# MINI51AN_v1 register map
File version: 1.0
Registers are 32-bit, read-write, reset 0x0 unless marked. A register's access mark holds for its fields unless they carry their own. Offsets are from the block's base; [hi:lo] are bit positions; {n}, {i} and the like mark numbered series; 'fields as' and 'values as' point back to an identical list.

## PWM — PWM Register Map
Base 0x40040000
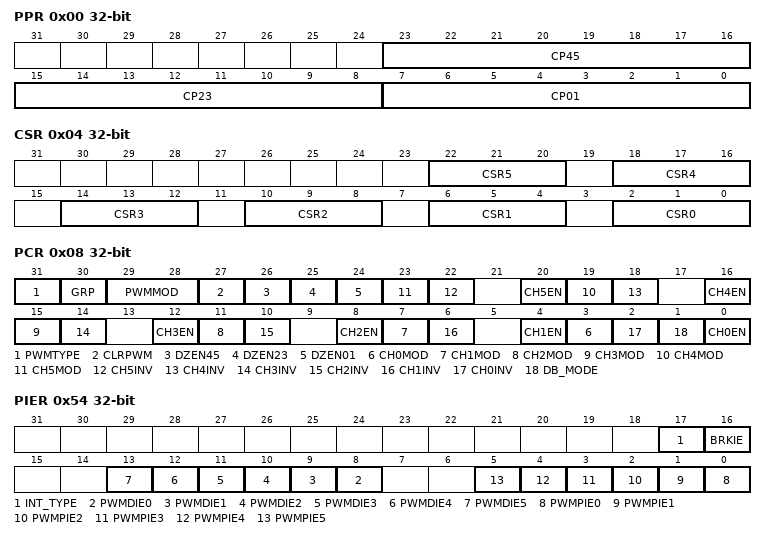
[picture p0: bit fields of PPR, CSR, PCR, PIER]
0x00 PPR — PWM Pre-scale Register
  [23:16] CP45 — Clock Prescaler 4 (PWM Counter 4 5 for group). Clock input is divided by (CP45 + 1) before it is fed to the corresponding PWM counter.
  [15:8] CP23 — Clock Prescaler 2 (PWM Counter 2 3 for group). Clock input is divided by (CP23 + 1) before it is fed to the corresponding PWM counter.
  [7:0] CP01 — Clock Prescaler 0 (PWM Counter 0 1 for group). Clock input is divided by (CP01 + 1) before it is fed to the corresponding PWM counter.
0x04 CSR — PWM Clock Select Register
  [22:20] CSR5 — Timer 5 Clock Source Selection
  [4n+2:4n] CSR{n} (n=0..4) — Timer {n} Clock Source Selection. Select clock input for PWM timer. (Table is the same as CSR5.)
0x08 PCR — PWM Control Register
  [31] PWMTYPE — PWM Aligned Type Selection Bit
    0=Edge-aligned type; 1=Center-aligned type
  [30] GRP — Group bit
    0=The signals timing of PWM0, PWM2 and PWM4 are independent; 1=Unify the signals timing of PWM0, PWM2 and PWM4 in the same phase which is controlled by PWM0
  [29:28] PWMMOD — PWM Operating Mode Selection
  [27] CLRPWM — Clear PWM Counter Control Bit. Note: It is automatically cleared by hardware.
    0=Do not clear PWM counter; 1=16-bit PWM counter cleared to 0x000
  [26] DZEN45 — Dead-zone 4 Generator Enable/Disable (PWM4 and PWM5 pair for PWM group). Note: When the dead-zone generator is enabled, the pair of PWM4 and PWM5 becomes a complementary pair for PWM group.
    0=Disabled; 1=Enabled
  [25] DZEN23 — Dead-zone 2 Generator Enable/Disable (PWM2 and PWM3 pair for PWM group). Note: When the dead-zone generator is enabled, the pair of PWM2 and PWM3 becomes a complementary pair for PWM group.
    0=Disabled; 1=Enabled
  [24] DZEN01 — Dead-zone 0 Generator Enable/Disable (PWM0 and PWM1 pair for PWM group). Note: When the dead-zone generator is enabled, the pair of PWM0 and PWM1 becomes a complementary pair for PWM group.
    0=Disabled; 1=Enabled
  [4n+3] CH{n}MOD (n=0..5) — PWM-Timer {n} Auto-reload/One-Shot Mode. Note: If there is a rising transition at this bit, it will cause CNR{n} and CMR{n} cleared.
    0=One-shot mode; 1=Auto-reload mode
  [22] CH5INV — PWM-Timer 5 Output Inverter ON/OFF. Note: Only even channels (PWM0, PWM2 and PWM4) can be set as inverter bit in independent mode.
    0=Inverter OFF; 1=Inverter ON
  [4n] CH{n}EN (n=0..5) — PWM-Timer {n} Enable/Disable Start Run
    0=Corresponding PWM-timer running Stopped; 1=Corresponding PWM-timer start run Enabled
  [18] CH4INV — PWM-Timer 4 Output Inverter ON/OFF
    0=Inverter OFF; 1=Inverter ON
  [14] CH3INV — PWM-Timer 3 Output Inverter ON/OFF. Note: Only even channels (PWM0, PWM2 and PWM4) can be set as inverter bit in independent mode.
    0=Inverter OFF; 1=Inverter ON
  [10] CH2INV — PWM-Timer 2 Output Inverter ON/OFF
    0=Inverter OFF; 1=Inverter ON
  [6] CH1INV — PWM-Timer 1 Output Inverter ON/OFF. Note: Only even channels (PWM0, PWM2 and PWM4) can be set as inverter bit in independent mode.
    0=Inverter OFF; 1=Inverter ON
  [2] CH0INV — PWM-Timer 0 Output Inverter ON/OFF
    0=Inverter OFF; 1=Inverter ON
  [1] DB_MODE — PWM Debug Mode Configuration Bit (Available in DEBUG mode only)
    0=Safe mode: The timer is frozen and PWM outputs are shut down Safe state for the inverter. The timer can still be re-started from where it stops; 1=Normal mode: The timer continues to operate normally May be dangerous in some cases since a constant duty cycle is applied to the inverter (no more interrupts serviced)
{0xC+4i} CNR{i} (i=0..5) — PWM Counter Register {i}
  [15:0] CNRn — PWM Counter/Timer Loaded Value. CNRn determines the PWM period. Edge-aligned mode: Note: Any write to CNRn will take effect in next PWM cycle.
{0x24+4i} CMR{i} (i=0..5) — PWM Comparator Register {i}
  [15:0] CMRn — PWM Comparator Register. CMR determines the PWM duty. Edge-aligned mode: Note: Any write to CMRn will take effect in next PWM cycle.
0x54 PIER — PWM Interrupt Enable Register
  [17] INT_TYPE — PWM Interrupt Type Selection Bit. Note: This bit is effective when PWM in central align mode only.
    0=PWMPIFn will be set if PWM counter underflows; 1=PWMPIFn will be set if PWM counter matches CNRn register
  [16] BRKIE — Enable Fault Brake0 and 1 Interrupt
    0=Disabling flags BKF0 and BKF1 to trigger PWM interrupt; 1=Enabling flags BKF0 and BKF1 can trigger PWM interrupt
  [n+8] PWMDIE{n} (n=0..5) — PWM Channel {n} Duty Interrupt Enable
    0=Disabled; 1=Enabled
  [n] PWMPIE{n} (n=0..5) — PWM Channel {n} Period Interrupt Enable
    0=Disabled; 1=Enabled
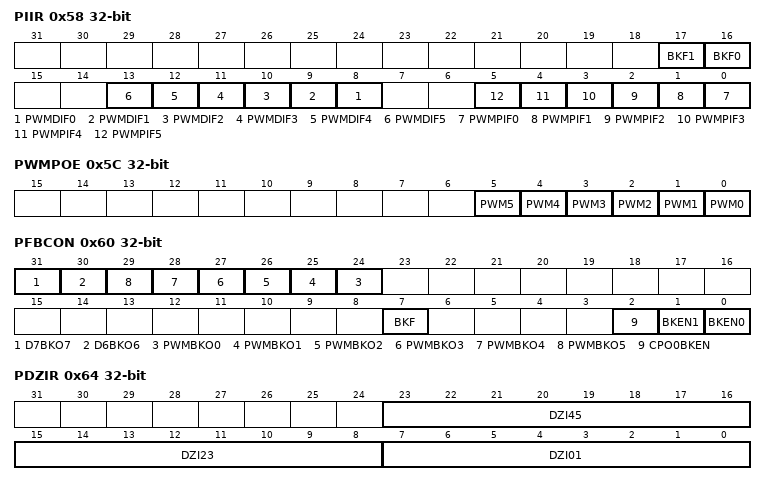
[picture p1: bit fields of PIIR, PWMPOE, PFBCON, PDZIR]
0x58 PIIR — PWM Interrupt Indication Register
  [17] BKF1 — PWM Brake1 Flag. Note: Software can write 1 to clear this bit.
    0=PWM Brake does not recognize a falling signal at BKP1; 1=When PWM Brake detects a falling signal at pin BKP1, this flag will be set to high
  [16] BKF0 — PWM Brake0 Flag. Note: Software can write 1 to clear this bit.
    0=PWM Brake does not recognize a falling signal at BKP0; 1=When PWM Brake detects a falling signal at pin BKP0, this flag will be set to high
  [n+8] PWMDIF{n} (n=0..5) — PWM channel {n} Duty Interrupt Flag. Flag is set by hardware when a channel {n} PWM counter reaches CMR{n}. Software can write 1 to clear this bit.
  [n] PWMPIF{n} (n=0..5) — PWM channel {n} Period Interrupt Flag. Flag is set by hardware when CNR{n} down counter reaches zero. Software can write 1 to clear this bit.
0x5C PWMPOE — PWM Output Enable for Channel 0~5
  [n] PWM{n} (n=0..5) — PWM Channel {n} Output Enable Register. Note: The corresponding GPIO pin also must be switched to PWM function.
    0=PWM channel {n} output to pin Disabled; 1=PWM channel {n} output to pin Enabled
0x60 PFBCON — PWM Fault Brake Control Register
  [31] D7BKO7 — D7 Brake Output Select Register
    0=D7 output low when fault brake conditions asserted; 1=D7 output high when fault brake conditions asserted
  [30] D6BKO6 — D6 Brake Output Select Register
    0=D6 output low when fault brake conditions asserted; 1=D6 output high when fault brake conditions asserted
  [n+24] PWMBKO{n} (n=0..5) — PWM Channel {n} Brake Output Select Register
    0=PWM output low when fault brake conditions asserted; 1=PWM output high when fault brake conditions asserted
  [7] BKF — PWM Fault Brake Event Flag (write 1 clear). Software can write 1 to clear this bit
    0=PWM output initial state when fault brake conditions asserted; 1=PWM output fault brake state when fault brake conditions asserted
  [2] CPO0BKEN — BKP1 Fault Brake Function Source Selection
    0=EINT1 as one brake source in BKP1; 1=CPO0 as one brake source in BKP1
  [1] BKEN1 — Enable BKP1 Pin Trigger Fault Brake Function 1
    0=Disabling BKP1 pin can trigger brake function 1 (EINT1 or CPO0); 1=Enabling a falling at BKP1 pin can trigger brake function 1
  [0] BKEN0 — Enable BKP0 Pin Trigger Fault Brake Function 0
    0=Disabling BKP0 pin can trigger brake function 0 (EINT0); 1=Enabling a falling at BKP0 pin can trigger brake function 0
0x64 PDZIR — PWM Dead-zone Interval Register
  [23:16] DZI45 — Dead-zone Interval Register for Pair of Channel4 and Channel5 (PWM4 and PWM5 pair). These 8 bits determine dead-zone length. The unit time of dead-zone length is received from corresponding CSR bits.
  [15:8] DZI23 — Dead-zone Interval Register for Pair of Channel2 and Channel3 (PWM2 and PWM3 pair). These 8 bits determine dead-zone length. The unit time of dead-zone length is received from corresponding CSR bits.
  [7:0] DZI01 — Dead-zone Interval Register for Pair of Channel0 and Channel1 (PWM0 and PWM1 pair). These 8 bits determine dead-zone length. The unit time of dead-zone length is received from corresponding CSR bits.
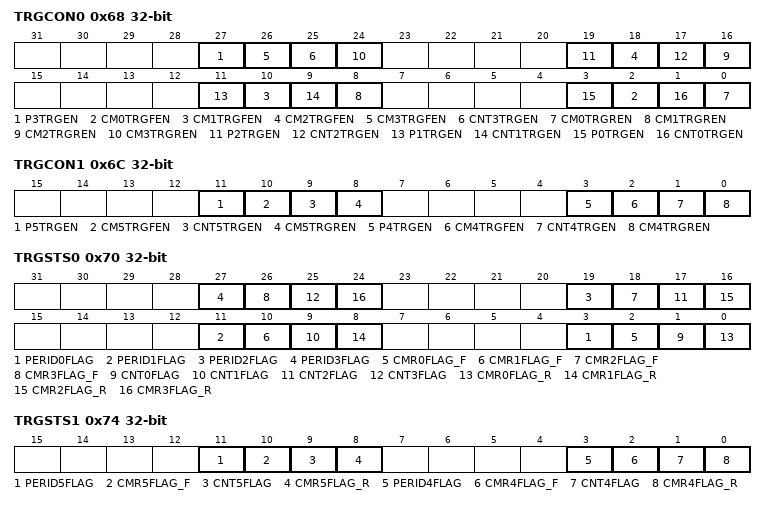
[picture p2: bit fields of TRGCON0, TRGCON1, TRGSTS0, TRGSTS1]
0x68 TRGCON0 — PWM Trigger Control Register 0
  [all] fields
    0=Disabled; 1=Enabled
  [27] P3TRGEN — Enable PWM trigger ADC function while Channel1's counter matching 0 in down-count direction. Note: This bit is valid for both center aligned mode and edged aligned mode.
  [8n+2] CM{n}TRGFEN (n=0..3) — Enable PWM trigger ADC function while Channel{n}'s counter matching CMR{n} in down-count direction. Note: This bit is valid for both center aligned mode and edged aligned mode.
  [25] CNT3TRGEN — Enable PWM trigger ADC function while Channel3's counter matching CNR3 in down-count direction. Note: This bit is only valid for PWM in center aligned mode. When PWM is in edged aligned mode, setting this bit is meaningless and will not take any effect.
  [8n] CM{n}TRGREN (n=0..3) — Enable PWM trigger ADC function while Channel{n}'s counter matching CMR{n} in up-count direction. Note: This bit is only valid for PWM in center aligned mode. When PWM is in edged aligned mode, setting this bit is meaningless and will not take any effect.
  [19] P2TRGEN — Enable PWM trigger ADC function while Channel2's counter matching 0 in down-count direction. Note: This bit is valid for both center aligned mode and edged aligned mode.
  [17] CNT2TRGEN — Enable PWM trigger ADC function while Channel2's counter matching CNR2 in down-count direction. Note: This bit is only valid for PWM in center aligned mode. When PWM is in edged aligned mode, setting this bit is meaningless and will not take any effect.
  [11] P1TRGEN — Enable PWM trigger ADC function while Channel1's counter matching 0 in down-count direction. Note: This bit is valid for both center aligned mode and edged aligned mode.
  [9] CNT1TRGEN — Enable PWM trigger ADC function while Channel1's counter matching CNR1 in down-count direction. Note: This bit is only valid for PWM in center aligned mode. When PWM is in edged aligned mode, setting this bit is meaningless and will not take any effect.
  [3] P0TRGEN — Enable PWM trigger ADC function while Channel0's counter matching 0 in down-count direction. Note: This bit is valid for both center aligned mode and edged aligned mode.
  [1] CNT0TRGEN — Enable PWM trigger ADC function while Channel0's counter matching CNR0 in up-count direction. Note: This bit is only valid for PWM in center aligned mode. When PWM is in edged aligned mode, setting this bit is meaningless and will not take any effect.
0x6C TRGCON1 — PWM Trigger Control Register 1
  [all] fields
    0=Disabled; 1=Enabled
  [11] P5TRGEN — Enable PWM trigger ADC function while Channel5's counter matching 0 in down-count direction. Note: This bit is valid for both center aligned mode and edged aligned mode.
  [10] CM5TRGFEN — Enable PWM trigger ADC function while Channel5's counter matching CMR5 in down-count direction. Note: This bit is valid for both center aligned mode and edged aligned mode.
  [9] CNT5TRGEN — Enable PWM trigger ADC function while Channel5's counter matching CNR5 in down-count direction. Note: This bit is only valid for PWM in center aligned mode. When PWM is in edged aligned mode, setting this bit is meaningless and will not take any effect.
  [8] CM5TRGREN — Enable PWM trigger ADC function while Channel5's counter matching CMR5 in up-count direction. Note: This bit is only valid for PWM in center aligned mode. When PWM is in edged aligned mode, setting this bit is meaningless and will not take any effect.
  [3] P4TRGEN — Enable PWM trigger ADC function while Channel4's counter matching 0 in down-count direction. Note: This bit is valid for both center aligned mode and edged aligned mode.
  [2] CM4TRGFEN — Enable PWM trigger ADC function while Channel4's counter matching CMR4 in down-count direction. Note: This bit is valid for both center aligned mode and edged aligned mode.
  [1] CNT4TRGEN — Enable PWM trigger ADC function while Channel4's counter matching CNR4 in down-count direction. Note: This bit is only valid for PWM in center aligned mode. When PWM is in edged aligned mode, setting this bit is meaningless and will not take any effect.
  [0] CM4TRGREN — Enable PWM trigger ADC function while Channel4's counter matching CMR4 in up-count direction. Note: This bit is only valid for PWM in center aligned mode. When PWM is in edged aligned mode, setting this bit is meaningless and will not take any effect.
0x70 TRGSTS0 — PWM Trigger Status Register 0
  [8n+3] PERID{n}FLAG (n=0..3) — ADC trigger flag by period. Note: Software can write 1 to clear this bit.
  [8n+2] CMR{n}FLAG_F (n=0..3) — ADC trigger flag by counting down to CMR. Note: Software can write 1 to clear this bit.
  [8n+1] CNT{n}FLAG (n=0..3) — ADC trigger flag by counting to CNR. Note: Software can write 1 to clear this bit.
  [8n] CMR{n}FLAG_R (n=0..3) — ADC trigger flag by counting up to CMR. Note: Software can write 1 to clear this bit.
0x74 TRGSTS1 — PWM Trigger Status Register 1
  [11] PERID5FLAG — ADC trigger flag by period. Note: Software can write 1 to clear this bit.
  [10] CMR5FLAG_F — ADC trigger flag by counting down to CMR. Note: Software can write 1 to clear this bit.
  [9] CNT5FLAG — ADC trigger flag by counting to CNR. Note: Software can write 1 to clear this bit.
  [8] CMR5FLAG_R — ADC trigger flag by counting up to CMR. Note: Software can write 1 to clear this bit.
  [3] PERID4FLAG — ADC trigger flag by period. Note: Software can write 1 to clear this bit.
  [2] CMR4FLAG_F — ADC trigger flag by counting down to CMR. Note: Software can write 1 to clear this bit.
  [1] CNT4FLAG — ADC trigger flag by counting to CNR. Note: Software can write 1 to clear this bit.
  [0] CMR4FLAG_R — ADC trigger flag by counting up to CMR. Note: Software can write 1 to clear this bit.
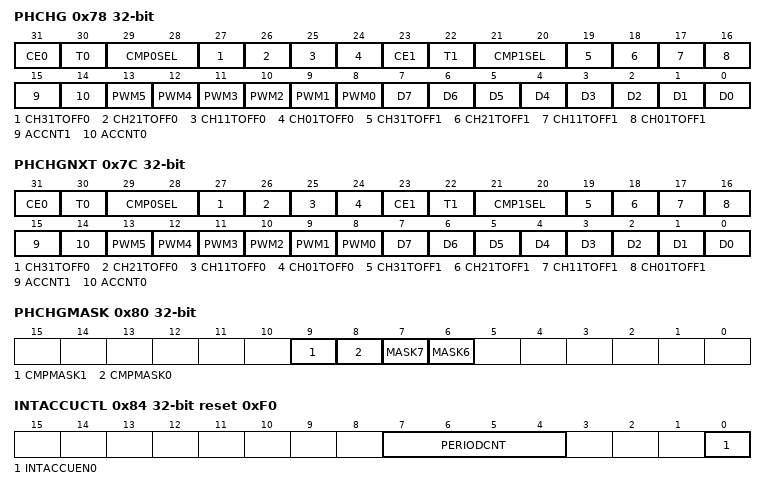
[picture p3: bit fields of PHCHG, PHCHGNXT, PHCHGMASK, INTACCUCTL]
0x78 PHCHG — Phase Changed Register
  [31] CE0 — Enable ACPM0 Trigger Function. Note: This bit will be auto cleared when ACMP0 trigger PWM if ACCNT0 is set.
    0=Disabled; 1=Enabled
  [30] T0 — Enable Timer0 trigger PWM function. When this bit is set, timer0 time-out event will update PHCHG with PHCHG_NXT register.
    0=Disabled; 1=Enabled
  [29:28] CMP0SEL — CMP0SEL. Select the input source of ACMP0.
    0=Select P1.5 as the input of ACMP0; 1=Select P1.0 as the input of ACMP0; 2=Select P1.2 as the input of ACMP0; 3=Select P1.3 as the input of ACMP0
  [27] CH31TOFF0 — Setting this bit will Force PWM3 to output low lasting for at most one period cycle as long as ACMP0 trigger it; this feature is usually in step motor application. Note: Only for PWM0, PWM1, PWM2, PWM3.
    0=Disabled; 1=Enabled
  [26] CH21TOFF0 — Setting this bit will Force PWM2 to output low lasting for at most one period cycle as long as ACMP0 trigger it; this feature is usually in step motor application. Note: Only for PWM0, PWM1, PWM2, PWM3.
    0=Disabled; 1=Enabled
  [25] CH11TOFF0 — Setting this bit will Force PWM1 to output low lasting for at most one period cycle as long as ACMP0 trigger it; this feature is usually in step motor application. Note: Only for PWM0, PWM1, PWM2, PWM3.
    0=Disabled; 1=Enabled
  [24] CH01TOFF0 — Setting this bit will Force PWM0 to output low lasting for at most one period cycle as long as ACMP0 trigger it; this feature is usually in step motor application. Note: Only for PWM0, PWM1, PWM2, PWM3.
    0=Disabled; 1=Enabled
  [23] CE1 — Enable ACPM1 Trigger Function. Note: This bit will be auto cleared when ACMP1 trigger PWM if ACCNT1 is set.
    0=Disabled; 1=Enabled
  [22] T1 — Enable Timer1 Trigger PWM Function. When this bit is set, timer1 time-out event will update PHCHG with PHCHG_NXT register.
    0=Disabled; 1=Enabled
  [21:20] CMP1SEL — CMP1SEL. Select the input source of ACMP1.
    0=Select P3.1 as the input of ACMP1; 1=Select P3.2 as the input of ACMP1; 2=Select P3.3 as the input of ACMP1; 3=Select P3.4 as the input of ACMP1
  [19] CH31TOFF1 — Setting this bit will Force PWM3 to output low lasting for at most one period cycle as long as ACMP1 trigger it; this feature is usually in step motor application. Note: Only for PWM0, PWM1, PWM2, PWM3.
    0=Disabled; 1=Enabled
  [18] CH21TOFF1 — Setting this bit will Force PWM2 to output low lasting for at most one period cycle as long as ACMP1 trigger it; this feature is usually in step motor application. Note: Only for PWM0, PWM1, PWM2, PWM3.
    0=Disabled; 1=Enabled
  [17] CH11TOFF1 — Setting this bit will Force PWM1 to output low lasting for at most one period cycle as long as ACMP1 trigger it; this feature is usually in step motor application. Note: Only for PWM0, PWM1, PWM2, PWM3.
    0=Disabled; 1=Enabled
  [16] CH01TOFF1 — Setting this bit will Force PWM0 to output low lasting for at most one period cycle as long as ACMP1 trigger it; this feature is usually in step motor application. Note: only for PWM0,PWM1,PWM2,PWM3.
    0=Disabled; 1=Enabled
  [15] ACCNT1 — Hardware auto clear CE1 when ACMP1 trigger it.
    0=Enabled; 1=Disabled
  [14] ACCNT0 — Hardware auto clear CE0 when ACMP0 trigger it.
    0=Enabled; 1=Disabled
  [n+8] PWM{n} (n=0..5) — PWM channel {n} output enable control.
    0=Output the original channel {n} waveform; 1=Output D{n} specified in bit {n} of PHCHG register
  [7] D7 — D7: when MASK1 is 1, channel 7's output waveform is D7.
    0=Output low; 1=Output high
  [6] D6 — D6: when MASK6 is 1, channel 6's output waveform is D6.
    0=Output low; 1=Output high
  [n] D{n} (n=0..5) — D{n}: when PWM{n} is zero, channel {n}'s output waveform is D{n}.
    0=Output low; 1=Output high
0x7C PHCHGNXT — Next Phase Change Register
  fields as PHCHG
0x80 PHCHGMASK — Phase Change MASK Register
  [9] CMPMASK1 — MASK for ACMP1
    0=The input of ACMP is controlled by CMP1CR; 1=The input of ACMP is controlled by CMP1SEL of PHCHG register
  [8] CMPMASK0 — MASK for ACMP0
    0=The input of ACMP is controlled by CMP0CR; 1=The input of ACMP is controlled by CMP0SEL of PHCHG register
  [7] MASK7 — MASK for D7
    0=Original GPIO P0.0; 1=D7
  [6] MASK6 — MASK for D6
    0=Original GPIO P0.1; 1=D6
0x84 INTACCUCTL reset 0xF0 — Period Interrupt Accumulation Control Register
  [7:4] PERIODCNT — Interrupt Accumulation Register. When INTACCUEN0 is set, PERIODCNT will decrease when every PWMPIF0 flag is set and when PERIODCNT reach to zero, the PWM0 interrupt will occurred and PERIODCNT will reload itself.
  [0] INTACCUEN0 — Enable Interrupt Accumulation Function
    0=Disabled; 1=Enabled
